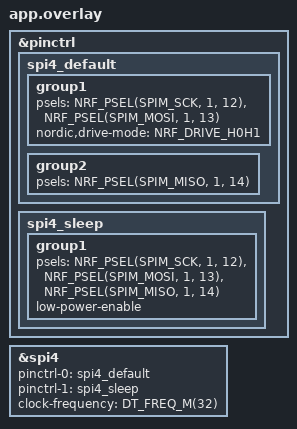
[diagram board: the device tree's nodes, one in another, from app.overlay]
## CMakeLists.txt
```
# SPDX-License-Identifier: Apache-2.0
#
# nRF5340 SPI Loopback + BLE Heart Rate — application CMakeLists.
# Targets board: nrf5340dk/nrf5340/cpuapp (sysbuild builds ipc_radio on cpunet).

cmake_minimum_required(VERSION 3.20.0)

find_package(Zephyr REQUIRED HINTS $ENV{ZEPHYR_BASE})
project(nrf5340_spi_loopback LANGUAGES C)

target_sources(app PRIVATE
    src/main.c
    src/spi_loopback.c
    src/ble_hrs.c
)

target_include_directories(app PRIVATE src)
```

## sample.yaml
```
# Twister / sample metadata for the nRF5340 SPI loopback + BLE HRS app.
# Enables `twister -T . -p nrf5340dk/nrf5340/cpuapp --build-only` regression.
sample:
  name: nRF5340 SPI Loopback + BLE Heart Rate
  description: >-
    32 MHz SPIM4 loopback self-test running alongside a BLE Heart Rate
    peripheral. Dual-core (app + ipc_radio on net core) via sysbuild.

common:
  sysbuild: true
  harness: console
  tags:
    - nrf5340
    - bluetooth
    - spi
  build_only: true

tests:
  sample.nrf5340.spi_loopback_ble_hrs:
    platform_allow:
      - nrf5340dk/nrf5340/cpuapp
    integration_platforms:
      - nrf5340dk/nrf5340/cpuapp
```

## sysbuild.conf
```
# Sysbuild top-level configuration for nRF5340 dual-core build.
# Net core runs the NCS `ipc_radio` sample configured as BLE HCI transport.

SB_CONFIG_NETCORE_IPC_RADIO=y
SB_CONFIG_NETCORE_IPC_RADIO_BT_HCI_IPC=y
```

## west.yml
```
# SPDX-License-Identifier: Apache-2.0
#
# West manifest — pulls nRF Connect SDK v3.3.0 (and its transitive Zephyr /
# nrfxlib / mcuboot / etc.) as siblings of this app.
#
# Usage:
#   west init -l <path-to-this-repo>
#   west update
#   west build -b nrf5340dk/nrf5340/cpuapp --sysbuild
#
manifest:
  version: "1.2"

  remotes:
    - name: ncs
      url-base: https://github.com/nrfconnect

  projects:
    - name: sdk-nrf
      remote: ncs
      repo-path: sdk-nrf
      path: nrf              # NCS hard-codes ${ZEPHYR_BASE}/../nrf/... in
                             # several Kconfig / sysbuild files, so the
                             # workspace path MUST be `nrf`.
      revision: v3.3.0
      import: true

  self:
    path: Nordic_nRF5340_SPI_loopback
    west-commands: ""
```

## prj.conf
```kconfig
# nRF5340 SPI Loopback + BLE Heart Rate — application Kconfig fragment.

# ---- Logging ----
CONFIG_LOG=y
CONFIG_LOG_MODE_DEFERRED=y
CONFIG_PRINTK=y
CONFIG_USE_SEGGER_RTT=y
CONFIG_LOG_BACKEND_RTT=y
CONFIG_LOG_BACKEND_UART=y

# ---- SPI (SPIM4 @ 32 MHz) ----
CONFIG_SPI=y
CONFIG_SPI_NRFX=y
CONFIG_SPI_ASYNC=n

# ---- Threading / scheduling ----
CONFIG_MAIN_STACK_SIZE=2048
CONFIG_SYSTEM_WORKQUEUE_STACK_SIZE=2048

# ---- Bluetooth (app core = BLE host) ----
CONFIG_BT=y
CONFIG_BT_PERIPHERAL=y
CONFIG_BT_DEVICE_NAME="nRF5340_HR"
CONFIG_BT_DEVICE_APPEARANCE=833
CONFIG_BT_MAX_CONN=1

# Heart Rate + Device Information services
CONFIG_BT_HRS=y
CONFIG_BT_DIS=y
CONFIG_BT_DIS_MANUF_NAME=y
CONFIG_BT_DIS_MANUF_NAME_STR="Nordic Semiconductor"
CONFIG_BT_DIS_MODEL_NUMBER=y
CONFIG_BT_DIS_MODEL_NUMBER_STR="nRF5340 DK"

# ---- BLE host/controller split (net core handles controller via IPC) ----

# ---- Misc quality-of-life ----
CONFIG_ASSERT=y
CONFIG_REBOOT=y
```

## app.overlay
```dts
/*
 * SPDX-License-Identifier: Apache-2.0
 *
 * Devicetree overlay for nRF5340 DK:
 *   - Enable SPIM4 at 32 MHz
 *   - Route SCK/MOSI/MISO to P1.12 / P1.13 / P1.14 (adjacent header pins,
 *     easy to jumper MOSI <-> MISO for loopback)
 *   - HIGH drive on SCK/MOSI for 32 MHz signal integrity (mandatory per
 *     nRF5340 OPS §6.19).
 */

&pinctrl {
	spi4_default: spi4_default {
		group1 {
			psels = <NRF_PSEL(SPIM_SCK,  1, 12)>,
				<NRF_PSEL(SPIM_MOSI, 1, 13)>;
			nordic,drive-mode = <NRF_DRIVE_H0H1>;
		};
		group2 {
			psels = <NRF_PSEL(SPIM_MISO, 1, 14)>;
		};
	};

	spi4_sleep: spi4_sleep {
		group1 {
			psels = <NRF_PSEL(SPIM_SCK,  1, 12)>,
				<NRF_PSEL(SPIM_MOSI, 1, 13)>,
				<NRF_PSEL(SPIM_MISO, 1, 14)>;
			low-power-enable;
		};
	};
};

&spi4 {
	status = "okay";
	pinctrl-0 = <&spi4_default>;
	pinctrl-1 = <&spi4_sleep>;
	pinctrl-names = "default", "sleep";
	clock-frequency = <DT_FREQ_M(32)>;
	/* No cs-gpios: chip-select is not used for a wire loopback test. */
};
```

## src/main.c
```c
/*
 * SPDX-License-Identifier: Apache-2.0
 *
 * nRF5340 SPI Loopback + BLE Heart Rate — entry point.
 *
 * Responsibilities:
 *   - Bring up the BLE stack + HRS peripheral (ble_hrs module)
 *   - Spawn the SPIM4 32 MHz loopback self-test thread (spi_loopback module)
 *   - Keep main() minimal; all real work lives in the sub-modules.
 */

#include "ble_hrs.h"
#include "spi_loopback.h"

#include <zephyr/kernel.h>
#include <zephyr/logging/log.h>

LOG_MODULE_REGISTER(main, LOG_LEVEL_INF);

int main(void)
{
	LOG_INF("nRF5340 SPI loopback + BLE HR starting");

	int err = ble_hrs_start();

	if (err) {
		LOG_ERR("ble_hrs_start failed: %d", err);
		return err;
	}

	err = spi_loopback_start();
	if (err) {
		LOG_ERR("spi_loopback_start failed: %d", err);
		return err;
	}

	LOG_INF("init complete");
	return 0;
}
```

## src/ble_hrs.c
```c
/*
 * SPDX-License-Identifier: Apache-2.0
 *
 * BLE Heart Rate peripheral for nRF5340 (app core hosts BT host; net core
 * runs the controller via IPC -- see sysbuild.conf).
 */

#include "ble_hrs.h"

#include <zephyr/bluetooth/bluetooth.h>
#include <zephyr/bluetooth/conn.h>
#include <zephyr/bluetooth/gatt.h>
#include <zephyr/bluetooth/services/hrs.h>
#include <zephyr/bluetooth/uuid.h>
#include <zephyr/kernel.h>
#include <zephyr/logging/log.h>

LOG_MODULE_REGISTER(ble_hrs, LOG_LEVEL_INF);

#define HR_NOTIFY_PERIOD_MS 1000

static const struct bt_data ad[] = {
	BT_DATA_BYTES(BT_DATA_FLAGS, (BT_LE_AD_GENERAL | BT_LE_AD_NO_BREDR)),
	BT_DATA_BYTES(BT_DATA_UUID16_ALL,
		      BT_UUID_16_ENCODE(BT_UUID_HRS_VAL),
		      BT_UUID_16_ENCODE(BT_UUID_DIS_VAL)),
};

static const struct bt_data sd[] = {
	BT_DATA(BT_DATA_NAME_COMPLETE, CONFIG_BT_DEVICE_NAME,
		sizeof(CONFIG_BT_DEVICE_NAME) - 1),
};

static struct bt_conn *current_conn;

static K_THREAD_STACK_DEFINE(hr_stack, 1024);
static struct k_thread hr_thread_data;

static void start_advertising(void)
{
	int err = bt_le_adv_start(BT_LE_ADV_CONN_FAST_1,
				  ad, ARRAY_SIZE(ad),
				  sd, ARRAY_SIZE(sd));
	if (err) {
		LOG_ERR("bt_le_adv_start failed: %d", err);
		return;
	}
	LOG_INF("advertising as \"%s\"", CONFIG_BT_DEVICE_NAME);
}

static void connected_cb(struct bt_conn *conn, uint8_t err)
{
	if (err) {
		LOG_WRN("connection failed (err 0x%02x)", err);
		return;
	}
	current_conn = bt_conn_ref(conn);
	LOG_INF("connected");
}

static void disconnected_cb(struct bt_conn *conn, uint8_t reason)
{
	LOG_INF("disconnected (reason 0x%02x)", reason);
	if (current_conn) {
		bt_conn_unref(current_conn);
		current_conn = NULL;
	}
	start_advertising();
}

BT_CONN_CB_DEFINE(conn_callbacks) = {
	.connected = connected_cb,
	.disconnected = disconnected_cb,
};

static uint16_t simulate_heart_rate(uint32_t tick)
{
	/* Triangle wave 60 -> 100 -> 60 bpm, 1 bpm per second. */
	uint32_t phase = tick % 80U;
	return (uint16_t)(60U + (phase < 40U ? phase : 80U - phase));
}

static void hr_notify_thread(void *p1, void *p2, void *p3)
{
	ARG_UNUSED(p1); ARG_UNUSED(p2); ARG_UNUSED(p3);

	uint32_t tick = 0;

	while (1) {
		k_msleep(HR_NOTIFY_PERIOD_MS);
		if (current_conn == NULL) {
			continue;
		}
		uint16_t hr = simulate_heart_rate(tick++);
		int err = bt_hrs_notify(hr);
		if (err) {
			LOG_WRN("bt_hrs_notify failed: %d", err);
		} else {
			LOG_DBG("hr = %u bpm", hr);
		}
	}
}

int ble_hrs_start(void)
{
	int err = bt_enable(NULL);

	if (err) {
		LOG_ERR("bt_enable failed: %d", err);
		return err;
	}
	LOG_INF("BLE stack enabled");

	start_advertising();

	k_tid_t tid = k_thread_create(&hr_thread_data, hr_stack,
				      K_THREAD_STACK_SIZEOF(hr_stack),
				      hr_notify_thread,
				      NULL, NULL, NULL,
				      K_PRIO_PREEMPT(8), 0, K_NO_WAIT);
	if (tid == NULL) {
		return -ENOMEM;
	}
	k_thread_name_set(tid, "hr_notify");
	return 0;
}
```

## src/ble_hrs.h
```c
/*
 * SPDX-License-Identifier: Apache-2.0
 *
 * BLE Heart Rate Service peripheral — simulates a heart-rate sensor and
 * notifies a connected central at 1 Hz.
 */

#ifndef APP_BLE_HRS_H_
#define APP_BLE_HRS_H_

/**
 * @brief Initialise BT, register HRS, start connectable advertising.
 *
 * Must be called after kernel init. Spawns a thread that emits a simulated
 * heart-rate value (60-100 bpm triangle wave) once per second when a central
 * is connected.
 *
 * @return 0 on success, negative errno otherwise.
 */
int ble_hrs_start(void);

#endif /* APP_BLE_HRS_H_ */
```

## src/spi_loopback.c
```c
/*
 * SPDX-License-Identifier: Apache-2.0
 *
 * SPIM4 32 MHz loopback test — sends a 32-byte incrementing pattern and
 * compares RX vs TX. Runs as an independent cooperative thread so it does
 * not block the BLE host.
 *
 * Implementation note:
 *   `SPI_DT_SPEC_GET` requires a declared child slave node on the bus.
 *   Our loopback has no real peripheral (MOSI is jumpered to MISO), so we
 *   grab the bus controller with `DEVICE_DT_GET` and build our own
 *   `struct spi_config`, reading the 32 MHz frequency from DT.
 */

#include "spi_loopback.h"

#include <zephyr/device.h>
#include <zephyr/devicetree.h>
#include <zephyr/drivers/spi.h>
#include <zephyr/kernel.h>
#include <zephyr/logging/log.h>
#include <string.h>

LOG_MODULE_REGISTER(spi_loopback, LOG_LEVEL_INF);

#define SPI_NODE        DT_NODELABEL(spi4)

/*
 * The `nrf5340bsim` simulator board has no SPIM4 peripheral, so the
 * `spi4` node does not exist in its devicetree. Compile the loopback
 * thread only on boards that actually provide the bus; on bsim,
 * `spi_loopback_start()` becomes a no-op so the BLE half of the app
 * still builds and runs under the simulator (covers P2 AC-R2).
 */
#if DT_NODE_EXISTS(SPI_NODE) && DT_NODE_HAS_STATUS(SPI_NODE, okay)

#define SPI_FREQ_HZ     DT_PROP(SPI_NODE, clock_frequency)
#define TEST_BUF_LEN    32U
#define TEST_PERIOD_MS  1000

static const struct device *const spi_dev = DEVICE_DT_GET(SPI_NODE);

static const struct spi_config spi_cfg = {
	.frequency = SPI_FREQ_HZ,
	.operation = SPI_OP_MODE_MASTER | SPI_TRANSFER_MSB | SPI_WORD_SET(8),
	.slave     = 0,
	/* .cs left zero-initialized: no CS line is driven in wire loopback. */
};

static K_THREAD_STACK_DEFINE(spi_stack, 1536);
static struct k_thread spi_thread_data;

static int run_one_transfer(uint32_t iteration)
{
	uint8_t tx_buf[TEST_BUF_LEN];
	uint8_t rx_buf[TEST_BUF_LEN];

	for (size_t i = 0; i < TEST_BUF_LEN; i++) {
		tx_buf[i] = (uint8_t)(iteration + i);
	}
	memset(rx_buf, 0, sizeof(rx_buf));

	const struct spi_buf tx = { .buf = tx_buf, .len = sizeof(tx_buf) };
	const struct spi_buf rx = { .buf = rx_buf, .len = sizeof(rx_buf) };
	const struct spi_buf_set tx_set = { .buffers = &tx, .count = 1 };
	const struct spi_buf_set rx_set = { .buffers = &rx, .count = 1 };

	int ret = spi_transceive(spi_dev, &spi_cfg, &tx_set, &rx_set);

	if (ret != 0) {
		LOG_ERR("spi_transceive failed: %d", ret);
		return ret;
	}

	if (memcmp(tx_buf, rx_buf, TEST_BUF_LEN) != 0) {
		LOG_ERR("loopback mismatch on iter %u", iteration);
		LOG_HEXDUMP_ERR(tx_buf, TEST_BUF_LEN, "TX");
		LOG_HEXDUMP_ERR(rx_buf, TEST_BUF_LEN, "RX");
		return -EIO;
	}

	LOG_INF("loopback OK (iter=%u, %u bytes @ %u Hz)",
		iteration, TEST_BUF_LEN, SPI_FREQ_HZ);
	return 0;
}

static void spi_loopback_thread(void *p1, void *p2, void *p3)
{
	ARG_UNUSED(p1); ARG_UNUSED(p2); ARG_UNUSED(p3);

	if (!device_is_ready(spi_dev)) {
		LOG_ERR("SPIM4 device not ready");
		return;
	}

	LOG_INF("SPIM4 loopback thread started (freq=%u Hz)", SPI_FREQ_HZ);

	uint32_t iter = 0;

	while (1) {
		(void)run_one_transfer(iter++);
		k_msleep(TEST_PERIOD_MS);
	}
}

int spi_loopback_start(void)
{
	k_tid_t tid = k_thread_create(&spi_thread_data, spi_stack,
				      K_THREAD_STACK_SIZEOF(spi_stack),
				      spi_loopback_thread,
				      NULL, NULL, NULL,
				      K_PRIO_PREEMPT(7), 0, K_NO_WAIT);
	if (tid == NULL) {
		return -ENOMEM;
	}
	k_thread_name_set(tid, "spi_loopback");
	return 0;
}

#else /* !DT_NODE_EXISTS(spi4) — e.g. nrf5340bsim */

int spi_loopback_start(void)
{
	LOG_WRN("spi4 node not present in devicetree; loopback disabled");
	return 0;
}

#endif
```

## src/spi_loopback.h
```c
/*
 * SPDX-License-Identifier: Apache-2.0
 *
 * SPI loopback self-test on SPIM4 @ 32 MHz.
 *
 * MOSI (P1.13) must be jumpered to MISO (P1.14) on the nRF5340 DK.
 */

#ifndef APP_SPI_LOOPBACK_H_
#define APP_SPI_LOOPBACK_H_

#include <stdint.h>

/**
 * @brief Start the SPI loopback test thread.
 *
 * Spawns a dedicated thread that periodically transmits a deterministic
 * 32-byte pattern on SPIM4 and verifies the received bytes match.
 *
 * @return 0 on success, negative errno otherwise.
 */
int spi_loopback_start(void);

#endif /* APP_SPI_LOOPBACK_H_ */
```
